# cm0 register map
Registers are 32-bit, read-write, no defined reset value unless marked. A register's access mark holds for its fields unless they carry their own. Offsets are from the block's base; lines under a group give offsets from that group; [hi:lo] are bit positions; {n}, {i} and the like mark numbered series; 'fields as' and 'values as' point back to an identical list; <NAME> marks a mode.

## Memory map
0xE0001000 DWT size 0x2C — Data Watchpoint Trace
0xE000E010 SysTick size 0x10 — 24Bit System Tick Timer for use in RTOS
0xE000E100 NVIC size 0x450
0xE000ED00 SCB size 0x8 — System control block
0xE000ED00 Debug size 0x100

## NVIC
Base 0xE000E100
0x00 NVIC_ISER ro — Interrupt Set-Enable Registers
0x80 NVIC_ICER ro — Interrupt Clear-Enable Registers
0x100 NVIC_ISPR ro — Interrupt Set-Pending Registers
0x180 NVIC_ICPR ro — Interrupt Clear-Pending Registers
{0x300+4i} NVIC_IPR[{i}] (i=0..7) ro — Interrupt Priority Register

## SCB — System control block
Base 0xE000ED00
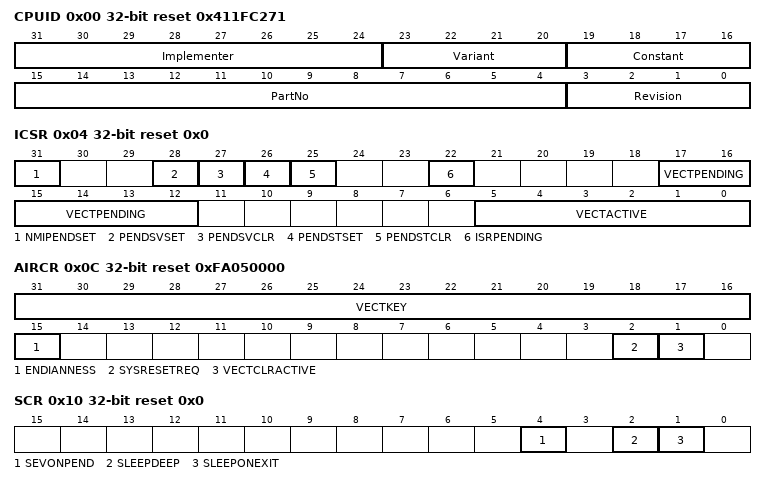
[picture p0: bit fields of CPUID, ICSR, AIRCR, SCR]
0x00 CPUID ro reset 0x411FC271 — CPUID Base Register
  [31:24] Implementer — Implementer code.
    65=ARM
  [23:20] Variant — Variant number, the r value in the rnpn product revision identifier.
    0=r0 (Revision 0); 1=r1 (Revision 1)
  [19:16] Constant — Reads as 0xF.
  [15:4] PartNo — Part number of the processor.
    0xC27=Cortex_M7 (Cortes-M7)
  [3:0] Revision — Revision number, the p value in the rnpn product revision identifier.
    0=p0 (Patch 0); 1=p1 (Patch 1); 2=p2 (Patch 2)
0x04 ICSR access per field reset 0x0 — Interrupt Control and State Register
  [31] NMIPENDSET rw — NMI set-pending bit.
  [28] PENDSVSET rw — PendSV set-pending bit.
  [27] PENDSVCLR wo — PendSV clear-pending bit.
  [26] PENDSTSET rw — SysTick exception set-pending bit.
  [25] PENDSTCLR wo — SysTick exception clear-pending bit.
  [22] ISRPENDING rw — Interrupt pending flag, excluding NMI and Faults
  [17:12] VECTPENDING ro — Indicates the exception number of the highest priority pending enabled exception.
  [5:0] VECTACTIVE ro — Contains the active exception number. Subtract 16 from this value to obtain the CMSIS IRQ number required to index into the Interrupt Clear-Enable, Set-Enable, Clear-Pending, Set-Pending or Priority Registers.
0x0C AIRCR access per field reset 0xFA050000 — Application Interrupt and Reset Control Register
  [31:16] VECTKEY rw — Register key. On write, write 0x5FA to VECTKEY, otherwise the write is ignored. Reads as 0xFA05
    0x5FA=Key (The write key); 0xFA05=Key_Read (The read key)
  [15] ENDIANNESS ro — Data endianness bit setting is implementation defined.
    0=Little_Endian (Data is little endian); 1=Big_Endian (Data is big endian)
  [2] SYSRESETREQ wo — System reset request bit setting is implementation defined.
  [1] VECTCLRACTIVE wo — Reserved for debug use. This bit reads as 0. When writing to the register youmust write 0 to this bit, otherwise behavior is Unpredictable.
0x10 SCR reset 0x0 — System Control Register
  [4] SEVONPEND — Send event on pending bit
  [2] SLEEPDEEP — Controls whether the processor uses sleep or deep sleep as its low-power mode
  [1] SLEEPONEXIT — Indicates sleep-on-exit when returning from Handler mode to Thread mode
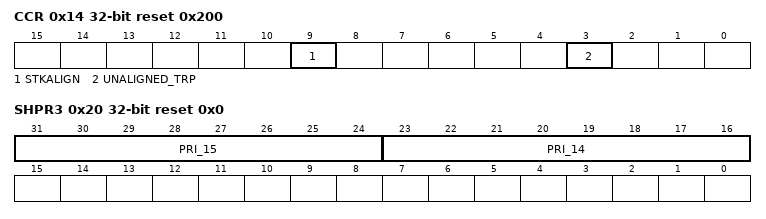
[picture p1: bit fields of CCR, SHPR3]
0x14 CCR access per field reset 0x200 — Configuration and Control Register
  [9] STKALIGN ro — Always reads-as-one. It indicates stack alignment on exception entry is 8-byte aligned.
  [3] UNALIGNED_TRP rw — Enables unalign access traps.
0x1C SHPR2 reset 0x0 — System Handler Priority Register 2
  [31:24] PRI_11 — Priority of the system handler, SVCall
0x20 SHPR3 reset 0x0 — System Handler Priority Register 3
  [31:24] PRI_15 — Priority of the system handler, SysTick
  [23:16] PRI_14 — Priority of the system handler, PendSV

## SysTick — 24Bit System Tick Timer for use in RTOS
Base 0xE000E010; register names take the prefix SYST_
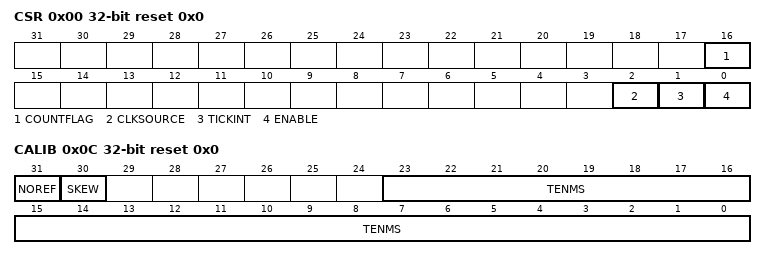
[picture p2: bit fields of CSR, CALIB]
0x00 CSR reset 0x0 — SysTick Control and Status Register
  [16] COUNTFLAG — SysTick counted to zero
  [2] CLKSOURCE — Source to count from
    0=External_Clk (External Clock); 1=CPU_Clk (CPU Clock)
  [1] TICKINT — Generate Tick Interrupt
    0=Disable (Counting down to zero asserts the SysTick exception request); 1=Enable (Counting down to zero does not assert the SysTick exception request)
  [0] ENABLE — Enable SysTick Timer
    0=Disable (counter disabled); 1=Enable (counter enabled)
0x04 RVR reset 0x0 — SysTick Reload Value Register
  [23:0] RELOAD — Value to auto reload SysTick after reaching zero
0x08 CVR reset 0x0 — SysTick Current Value Register
  [23:0] CURRENT — Current value
0x0C CALIB ro reset 0x0 — SysTick Calibration Value Register
  [31] NOREF
    0=Ref_Clk_Available; 1=Ref_Clk_Unavailable (Ref Clk not available)
  [30] SKEW — Clock Skew
    0=Exact (10ms calibration value is exact); 1=Inexact (10ms calibration value is inexact, because of the clock frequency)
  [23:0] TENMS — Reload value to use for 10ms timing

## Debug
Base 0xE000ED00
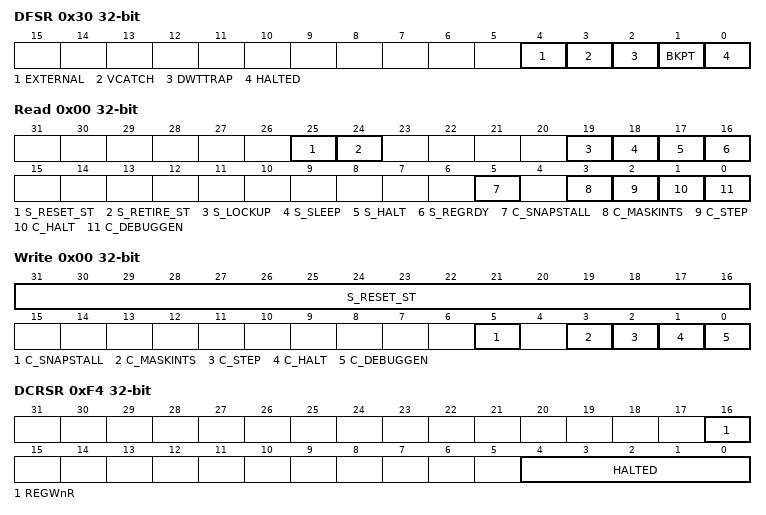
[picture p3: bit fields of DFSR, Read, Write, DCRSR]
0x30 DFSR — Debug Fault Status Register
  [4] EXTERNAL — An asynchronous exception generated due to the assertion of EDBGRQ.
  [3] VCATCH — Vector catch triggered. Corresponding FSR will contain the primary cause of the exception.
  [2] DWTTRAP — Data Watchpoint and Trace trap. Indicates that the core halted due to at least one DWT trap event.
  [1] BKPT — BKPT instruction executed or breakpoint match in FPB.
  [0] HALTED
0xF0 DHCSR group — Debug Halting Control and Status Register
  0x00 Read ro
    [25] S_RESET_ST, [24] S_RETIRE_ST, [19] S_LOCKUP, [18] S_SLEEP, [17] S_HALT, [16] S_REGRDY, [5] C_SNAPSTALL, [3] C_MASKINTS, [2] C_STEP, [1] C_HALT, [0] C_DEBUGGEN
  0x00 Write wo (alternate view of DHCSR_Read)
    [31:16] S_RESET_ST — Debug Key. The value 0xA05F must be written to enable write accesses to bits [15:0], otherwise the write access will be ignored. Read behavior of bits [31:16] is as listed below.
    [5] C_SNAPSTALL
    [3] C_MASKINTS
    [2] C_STEP
    [1] C_HALT
    [0] C_DEBUGGEN
0xF4 DCRSR wo — Debug Core Register Selector Register: The DCRSR write-only register generates a handshake to the core to transfer the selected register to/from the DCRDR. The DHCSR S_REGRDY bit is cleared when the DCRSR is written, and remains clear until the core transaction completes. This register is only accessible from Debug state.
  [16] REGWnR
    1=Write; 0=Read
  [4:0] HALTED
    {v}=Register_{v} (v=0..12); 13=Current_SP; 14=Link_Rregister; 15=Debug_Return_Address; 16=xPSR; 17=MSP; 18=PSP; 19=CONTROL_FAULTMASK_BASEPRI_PRIMASK
0xF8 DCRDR — Debug Core Register Data Register
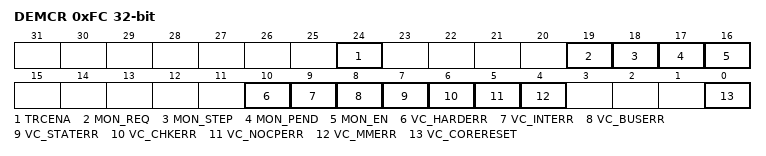
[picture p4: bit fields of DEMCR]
0xFC DEMCR — Debug Exception and Monitor Control Register
  [24] TRCENA, [19] MON_REQ, [18] MON_STEP, [17] MON_PEND, [16] MON_EN, [10] VC_HARDERR, [9] VC_INTERR, [8] VC_BUSERR, [7] VC_STATERR, [6] VC_CHKERR, [5] VC_NOCPERR, [4] VC_MMERR, [0] VC_CORERESET

## DWT — Data Watchpoint Trace
Base 0xE0001000
0x00 CTRL — Control Register
  [31:28] NUMCOMP — Number of comparators available
0x1C PCSR — Program Counter Sample Register
0x20 COMP0 — Comparator Register 0
0x24 MASK0 — Mask Register 0
0x28 FUNCTION0 — Function Register 0

## Notices in the file
Copyright (C) 2016 AdaCore
